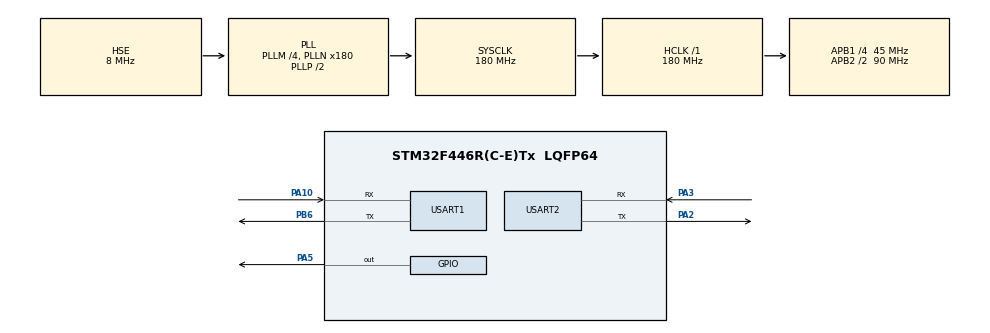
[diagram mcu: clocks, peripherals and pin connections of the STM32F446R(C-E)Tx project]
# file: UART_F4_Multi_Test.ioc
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Dma.Request0=USART1_RX
Dma.USART1_RX.0.Direction=DMA_PERIPH_TO_MEMORY
Dma.USART1_RX.0.FIFOMode=DMA_FIFOMODE_DISABLE
Dma.USART1_RX.0.Instance=DMA2_Stream2
Dma.USART1_RX.0.MemDataAlignment=DMA_MDATAALIGN_BYTE
Dma.USART1_RX.0.MemInc=DMA_MINC_ENABLE
Dma.USART1_RX.0.Mode=DMA_NORMAL
Dma.USART1_RX.0.PeriphDataAlignment=DMA_PDATAALIGN_BYTE
Dma.USART1_RX.0.PeriphInc=DMA_PINC_DISABLE
Dma.USART1_RX.0.Priority=DMA_PRIORITY_LOW
Mcu.Family=STM32F4
Mcu.Name=STM32F446R(C-E)Tx
Mcu.Package=LQFP64
NVIC.DMA2_Stream2_IRQn=true\:0\:0\:false\:false\:true\:false\:true
NVIC.PriorityGroup=NVIC_PRIORITYGROUP_4
NVIC.USART1_IRQn=true\:0\:0\:false\:false\:true\:true\:true
PA10.Mode=Asynchronous
PA10.Signal=USART1_RX
PA2.Mode=Asynchronous
PA2.Signal=USART2_TX
PA3.Mode=Asynchronous
PA3.Signal=USART2_RX
PA5.Signal=GPIO_Output
PB6.Mode=Asynchronous
PB6.Signal=USART1_TX
PH0-OSC_IN.Mode=HSE-External-Clock-Source
PH0-OSC_IN.Signal=RCC_OSC_IN
PH1-OSC_OUT.Mode=HSE-External-Clock-Source
PH1-OSC_OUT.Signal=RCC_OSC_OUT
ProjectManager.HeapSize=0x200
ProjectManager.StackSize=0x400
ProjectManager.TargetToolchain=STM32CubeIDE
RCC.AHBFreq_Value=180000000
RCC.APB1CLKDivider=RCC_HCLK_DIV4
RCC.APB1Freq_Value=45000000
RCC.APB1TimFreq_Value=90000000
RCC.APB2CLKDivider=RCC_HCLK_DIV2
RCC.APB2Freq_Value=90000000
RCC.APB2TimFreq_Value=180000000
RCC.CortexFreq_Value=180000000
RCC.HCLKFreq_Value=180000000
RCC.HSE_VALUE=8000000
RCC.PLLM=4
RCC.PLLN=180
RCC.PLLSourceVirtual=RCC_PLLSOURCE_HSE
RCC.SYSCLKFreq_VALUE=180000000
RCC.SYSCLKSource=RCC_SYSCLKSOURCE_PLLCLK
RCC.USBFreq_Value=180000000
RCC.VCOOutputFreq_Value=360000000
USART1.VirtualMode=VM_ASYNC
USART2.VirtualMode=VM_ASYNC
board=custom

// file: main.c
/* USER CODE BEGIN Header */
/**
  ******************************************************************************
  * @file           : main.c
  * @brief          : Main program body
  ******************************************************************************
  * @attention
  *
  * <h2><center>&copy; Copyright (c) 2021 STMicroelectronics.
  * All rights reserved.</center></h2>
  *
  * This software component is licensed by ST under BSD 3-Clause license,
  * the "License"; You may not use this file except in compliance with the
  * License. You may obtain a copy of the License at:
  *                        opensource.org/licenses/BSD-3-Clause
  *
  ******************************************************************************
  */
/* USER CODE END Header */
#include "main.h"

/* USER CODE BEGIN Includes */

#include "uartRingBufDMA.h"

/* USER CODE END Includes */

UART_HandleTypeDef huart2;
DMA_HandleTypeDef hdma_usart2_rx;

void SystemClock_Config(void);
static void MX_GPIO_Init(void);
static void MX_USART2_UART_Init(void);
static void MX_DMA_Init(void);

/* USER CODE BEGIN 0 */
char buffer[100];
/* USER CODE END 0 */

int main(void)
{

  /* MCU Configuration--------------------------------------------------------*/

  /* Reset of all peripherals, Initializes the Flash interface and the Systick. */
  HAL_Init();

  /* Configure the system clock */
  SystemClock_Config();

  /* Initialize all configured peripherals */
  MX_GPIO_Init();
  MX_USART2_UART_Init();
  MX_DMA_Init();
  MX_USART1_UART_Init();
  /* USER CODE BEGIN 2 */

  Ringbuf_Init();

//  if (isConfirmed(5000) != 1)
//  {
//	  Error_Handler();
//  }

//  if (waitFor("hello", 6000)!= 1)
//  {
//	  Error_Handler();
//  }

//  if (copyUpto("hello", buffer, 6000)!= 1)
//  {
//	  Error_Handler();
//  }

  if (getAfter("hello", 4, buffer, 6000)!= 1)
  {
	  Error_Handler();
  }

  /* USER CODE END 2 */

  /* Infinite loop */
  while (1)
  {

    /* USER CODE BEGIN 3 */

	  HAL_Delay (1000);
  }
  /* USER CODE END 3 */
}

void SystemClock_Config(void)
{
  RCC_OscInitTypeDef RCC_OscInitStruct = {0};
  RCC_ClkInitTypeDef RCC_ClkInitStruct = {0};

  /** Configure the main internal regulator output voltage
  */
  __HAL_RCC_PWR_CLK_ENABLE();
  __HAL_PWR_VOLTAGESCALING_CONFIG(PWR_REGULATOR_VOLTAGE_SCALE1);
  /** Initializes the RCC Oscillators according to the specified parameters
  * in the RCC_OscInitTypeDef structure.
  */
  RCC_OscInitStruct.OscillatorType = RCC_OSCILLATORTYPE_HSE;
  RCC_OscInitStruct.HSEState = RCC_HSE_ON;
  RCC_OscInitStruct.PLL.PLLState = RCC_PLL_ON;
  RCC_OscInitStruct.PLL.PLLSource = RCC_PLLSOURCE_HSE;
  RCC_OscInitStruct.PLL.PLLM = 4;
  RCC_OscInitStruct.PLL.PLLN = 180;
  RCC_OscInitStruct.PLL.PLLP = RCC_PLLP_DIV2;
  RCC_OscInitStruct.PLL.PLLQ = 2;
  RCC_OscInitStruct.PLL.PLLR = 2;
  if (HAL_RCC_OscConfig(&RCC_OscInitStruct) != HAL_OK)
  {
    Error_Handler();
  }
  /** Activate the Over-Drive mode
  */
  if (HAL_PWREx_EnableOverDrive() != HAL_OK)
  {
    Error_Handler();
  }
  /** Initializes the CPU, AHB and APB buses clocks
  */
  RCC_ClkInitStruct.ClockType = RCC_CLOCKTYPE_HCLK|RCC_CLOCKTYPE_SYSCLK
                              |RCC_CLOCKTYPE_PCLK1|RCC_CLOCKTYPE_PCLK2;
  RCC_ClkInitStruct.SYSCLKSource = RCC_SYSCLKSOURCE_PLLCLK;
  RCC_ClkInitStruct.AHBCLKDivider = RCC_SYSCLK_DIV1;
  RCC_ClkInitStruct.APB1CLKDivider = RCC_HCLK_DIV4;
  RCC_ClkInitStruct.APB2CLKDivider = RCC_HCLK_DIV2;

  if (HAL_RCC_ClockConfig(&RCC_ClkInitStruct, FLASH_LATENCY_5) != HAL_OK)
  {
    Error_Handler();
  }
}

static void MX_USART2_UART_Init(void)
{

  huart2.Instance = USART2;
  huart2.Init.BaudRate = 115200;
  huart2.Init.WordLength = UART_WORDLENGTH_8B;
  huart2.Init.StopBits = UART_STOPBITS_1;
  huart2.Init.Parity = UART_PARITY_NONE;
  huart2.Init.Mode = UART_MODE_TX_RX;
  huart2.Init.HwFlowCtl = UART_HWCONTROL_NONE;
  huart2.Init.OverSampling = UART_OVERSAMPLING_16;
  if (HAL_UART_Init(&huart2) != HAL_OK)
  {
    Error_Handler();
  }

}

static void MX_DMA_Init(void)
{

  /* DMA controller clock enable */
  __HAL_RCC_DMA2_CLK_ENABLE();

  /* DMA interrupt init */
  /* DMA2_Stream2_IRQn interrupt configuration */
  HAL_NVIC_SetPriority(DMA1_Stream5_IRQn, 0, 0);
  HAL_NVIC_EnableIRQ(DMA1_Stream5_IRQn);

}

static void MX_GPIO_Init(void)
{

  /* GPIO Ports Clock Enable */
  __HAL_RCC_GPIOH_CLK_ENABLE();
  __HAL_RCC_GPIOA_CLK_ENABLE();
  __HAL_RCC_GPIOB_CLK_ENABLE();

}

void Error_Handler(void)
{
  __disable_irq();
  while (1)
  {
  }
}

/************************ (C) COPYRIGHT STMicroelectronics *****END OF FILE****/
